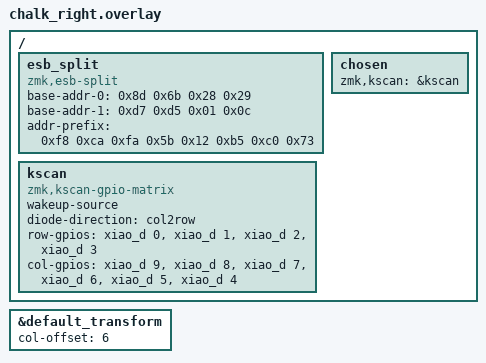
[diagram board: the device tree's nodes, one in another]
#include "chalk.dtsi" 


/ {
    esb_split {
        compatible = "zmk,esb-split";
        // These are arbitrary default addresses. In end user products
        // different addresses should be used for each set of devices.
        base-addr-0 = <0x8d 0x6b 0x28 0x29>;
        base-addr-1 = <0xd7 0xd5 0x01 0x0c>;
        addr-prefix = <0xf8 0xca 0xfa 0x5b 0x12 0xb5 0xc0 0x73>;
    };
};


/{
    chosen {
        zmk,kscan = &kscan;
    };

    kscan: kscan {
        compatible = "zmk,kscan-gpio-matrix";
        wakeup-source;

        diode-direction = "col2row";

        row-gpios = <&xiao_d 0 (GPIO_ACTIVE_HIGH | GPIO_PULL_DOWN)>
                    , <&xiao_d 1 (GPIO_ACTIVE_HIGH | GPIO_PULL_DOWN)>
                    , <&xiao_d 2 (GPIO_ACTIVE_HIGH | GPIO_PULL_DOWN)>
                    , <&xiao_d 3 (GPIO_ACTIVE_HIGH | GPIO_PULL_DOWN)>
                    ;

        col-gpios = <&xiao_d 9  GPIO_ACTIVE_HIGH>
                    , <&xiao_d 8  GPIO_ACTIVE_HIGH>
                    , <&xiao_d 7  GPIO_ACTIVE_HIGH>
                    , <&xiao_d 6  GPIO_ACTIVE_HIGH>
                    , <&xiao_d 5  GPIO_ACTIVE_HIGH>
                    , <&xiao_d 4  GPIO_ACTIVE_HIGH>
                    ;
    };
};

&default_transform {
    col-offset = <6>;
};


